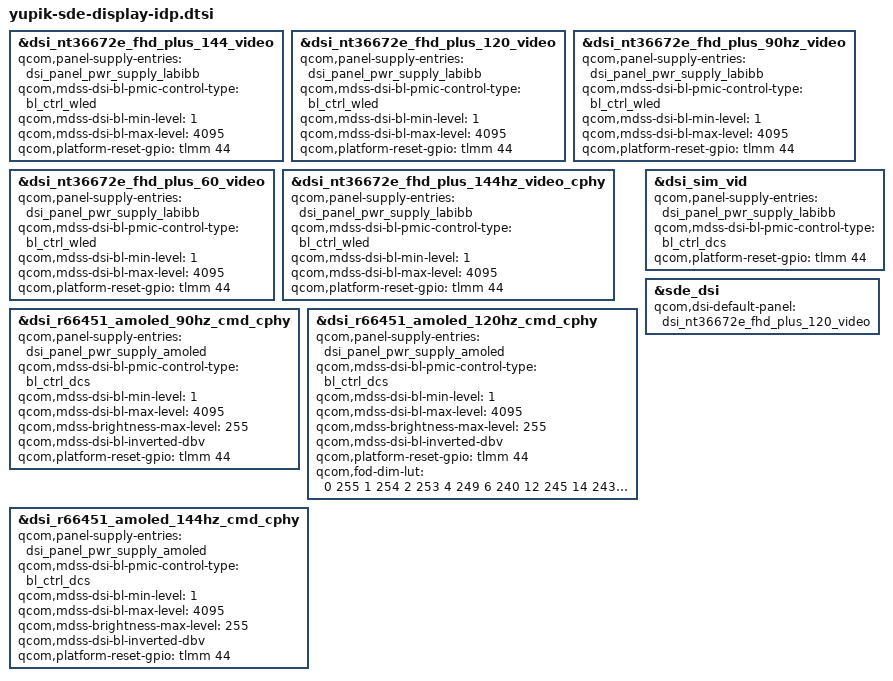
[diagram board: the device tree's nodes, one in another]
#include "yupik-sde-display.dtsi"

&dsi_nt36672e_fhd_plus_144_video {
	qcom,panel-supply-entries = <&dsi_panel_pwr_supply_labibb>;
	qcom,mdss-dsi-bl-pmic-control-type = "bl_ctrl_wled";
	qcom,mdss-dsi-bl-min-level = <1>;
	qcom,mdss-dsi-bl-max-level = <4095>;
	qcom,platform-reset-gpio = <&tlmm 44 0>;
};

&dsi_nt36672e_fhd_plus_120_video {
	qcom,panel-supply-entries = <&dsi_panel_pwr_supply_labibb>;
	qcom,mdss-dsi-bl-pmic-control-type = "bl_ctrl_wled";
	qcom,mdss-dsi-bl-min-level = <1>;
	qcom,mdss-dsi-bl-max-level = <4095>;
	qcom,platform-reset-gpio = <&tlmm 44 0>;
};

&dsi_nt36672e_fhd_plus_90hz_video {
	qcom,panel-supply-entries = <&dsi_panel_pwr_supply_labibb>;
	qcom,mdss-dsi-bl-pmic-control-type = "bl_ctrl_wled";
	qcom,mdss-dsi-bl-min-level = <1>;
	qcom,mdss-dsi-bl-max-level = <4095>;
	qcom,platform-reset-gpio = <&tlmm 44 0>;
};

&dsi_nt36672e_fhd_plus_60_video {
	qcom,panel-supply-entries = <&dsi_panel_pwr_supply_labibb>;
	qcom,mdss-dsi-bl-pmic-control-type = "bl_ctrl_wled";
	qcom,mdss-dsi-bl-min-level = <1>;
	qcom,mdss-dsi-bl-max-level = <4095>;
	qcom,platform-reset-gpio = <&tlmm 44 0>;
};

&dsi_nt36672e_fhd_plus_144hz_video_cphy {
	qcom,panel-supply-entries = <&dsi_panel_pwr_supply_labibb>;
	qcom,mdss-dsi-bl-pmic-control-type = "bl_ctrl_wled";
	qcom,mdss-dsi-bl-min-level = <1>;
	qcom,mdss-dsi-bl-max-level = <4095>;
	qcom,platform-reset-gpio = <&tlmm 44 0>;
};

&dsi_r66451_amoled_90hz_cmd_cphy {
	qcom,panel-supply-entries = <&dsi_panel_pwr_supply_amoled>;
	qcom,mdss-dsi-bl-pmic-control-type = "bl_ctrl_dcs";
	qcom,mdss-dsi-bl-min-level = <1>;
	qcom,mdss-dsi-bl-max-level = <4095>;
	qcom,mdss-brightness-max-level = <255>;
	qcom,mdss-dsi-bl-inverted-dbv;
	qcom,platform-reset-gpio = <&tlmm 44 0>;
};

&dsi_r66451_amoled_120hz_cmd_cphy {
	qcom,panel-supply-entries = <&dsi_panel_pwr_supply_amoled>;
	qcom,mdss-dsi-bl-pmic-control-type = "bl_ctrl_dcs";
	qcom,mdss-dsi-bl-min-level = <1>;
	qcom,mdss-dsi-bl-max-level = <4095>;
	qcom,mdss-brightness-max-level = <255>;
	qcom,mdss-dsi-bl-inverted-dbv;
	qcom,platform-reset-gpio = <&tlmm 44 0>;
	qcom,fod-dim-lut = <
                /* brightness, alpha */
                        0	255
                        1	254
                        2	253
                        4	249
                        6	240
                        12	245
                        14	243
                        28	242
                        42	241
                        57	239
                        71	238
                        85	237
                        100	236
                        112	234
                        125	233
                        137	232
                        150	231
                        162	229
                        175	228
                        187	227
                        200	225
                        221	224
                        243	223
                        265	222
                        286	220
                        308	219
                        330	218
                        351	217
                        373	215
                        395	214
                        417	213
                        438	211
                        460	210
                        482	209
                        503	208
                        525	206
                        547	205
                        569	204
                        590	203
                        612	201
                        634	200
                        655	199
                        677	197
                        699	196
                        721	195
                        742	194
                        764	192
                        786	191
                        807	190
                        829	189
                        851	187
                        873	186
                        894	185
                        916	183
                        938	182
                        959	181
                        981	180
                        1003	178
                        1024	177
                        1046	176
                        1068	175
                        1090	173
                        1111	172
                        1133	171
                        1155	169
                        1176	168
                        1198	167
                        1220	166
                        1242	164
                        1263	163
                        1285	162
                        1307	161
                        1328	159
                        1350	158
                        1372	157
                        1394	155
                        1415	154
                        1437	153
                        1459	152
                        1480	150
                        1502	149
                        1524	148
                        1546	147
                        1567	145
                        1589	144
                        1611	143
                        1632	141
                        1654	140
                        1676	139
                        1698	138
                        1719	136
                        1741	135
                        1763	134
                        1784	133
                        1806	131
                        1828	130
                        1849	129
                        1871	127
                        1893	126
                        1915	125
                        1936	124
                        1958	122
                        1980	121
                        2001	120
                        2023	119
                        2045	117
                        2067	116
                        2088	115
                        2110	113
                        2132	112
                        2153	111
                        2175	110
                        2197	108
                        2219	107
                        2240	106
                        2262	105
                        2284	103
                        2305	102
                        2327	101
                        2349	99
                        2371	98
                        2392	97
                        2414	96
                        2436	94
                        2457	93
                        2479	92
                        2501	91
                        2523	89
                        2544	88
                        2566	87
                        2588	85
                        2609	84
                        2631	83
                        2653	82
                        2674	80
                        2696	79
                        2718	78
                        2740	77
                        2761	75
                        2783	74
                        2805	73
                        2826	71
                        2848	70
                        2870	69
                        2892	68
                        2913	66
                        2935	65
                        2957	64
                        2978	63
                        3000	61
                        3022	60
                        3044	59
                        3065	57
                        3087	56
                        3109	55
                        3130	54
                        3152	52
                        3174	51
                        3196	50
                        3217	49
                        3239	47
                        3261	46
                        3282	45
                        3304	43
                        3326	42
                        3348	41
                        3369	40
                        3391	38
                        3413	37
                        3434	36
                        3456	35
                        3478	33
                        3499	32
                        3521	31
                        3541	29
	>;
};

&dsi_r66451_amoled_144hz_cmd_cphy {
	qcom,panel-supply-entries = <&dsi_panel_pwr_supply_amoled>;
	qcom,mdss-dsi-bl-pmic-control-type = "bl_ctrl_dcs";
	qcom,mdss-dsi-bl-min-level = <1>;
	qcom,mdss-dsi-bl-max-level = <4095>;
	qcom,mdss-brightness-max-level = <255>;
	qcom,mdss-dsi-bl-inverted-dbv;
	qcom,platform-reset-gpio = <&tlmm 44 0>;
};

&dsi_sim_vid {
	qcom,panel-supply-entries = <&dsi_panel_pwr_supply_labibb>;
	qcom,mdss-dsi-bl-pmic-control-type = "bl_ctrl_dcs";
	qcom,platform-reset-gpio = <&tlmm 44 0>;
};

&sde_dsi {
	qcom,dsi-default-panel = <&dsi_nt36672e_fhd_plus_120_video>;
};

